# AST1060 register map
File version: 1.0
CPU: CM4 r0p1, little endian, MPU, FPU, 4 interrupt priority bits, 256 interrupts
Registers are 32-bit, read-write, reset 0x0 unless marked. A register's access mark holds for its fields unless they carry their own. Offsets are from the block's base; [hi:lo] are bit positions; {n}, {i} and the like mark numbered series; 'fields as' and 'values as' point back to an identical list.

## spi
Base 0x7E630000
Same registers: spi1 0x7E640000
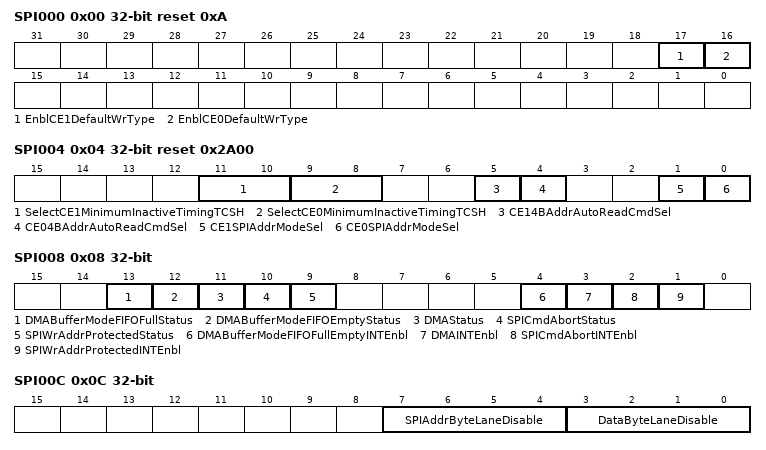
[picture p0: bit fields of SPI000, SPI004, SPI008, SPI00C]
0x00 SPI000 reset 0xA — SPI Flash Configuration Register
  [17] EnblCE1DefaultWrType — Enable CE1 default write type
  [16] EnblCE0DefaultWrType — Enable CE0 default write type
    0=CEx_Is_Default_At_Write_Disable_Mode; 1=CEx_Is_Default_At_Write_Enable_Mode
0x04 SPI004 reset 0x2A00 — CE Control Register
  [11:10] SelectCE1MinimumInactiveTimingTCSH
  [9:8] SelectCE0MinimumInactiveTimingTCSH
    0=16_X_HCLK; 1=24_X_HCLK; 2=32_X_HCLK; 3=40_X_HCLK
  [5] CE14BAddrAutoReadCmdSel — CE1 4B address Auto-Read command selection
  [4] CE04BAddrAutoReadCmdSel — CE0 4B address Auto-Read command selection
    0=Use_0x03_Command; 1=Use_0x13_Command
  [1] CE1SPIAddrModeSel — CE1 SPI address mode selection
  [0] CE0SPIAddrModeSel — CE0 SPI address mode selection
    0=3B3_Bytes_Smaller_Than_Or_Equal_To_16MB; 1=4B4_Bytes_Larger_Than_16MB
0x08 SPI008 — Interrupt Control and Status Register
  [13] DMABufferModeFIFOFullStatus ro
    0=FIFO_Is_Nonfull; 1=FIFO_Is_Full
  [12] DMABufferModeFIFOEmptyStatus ro
    0=FIFO_Is_Nonempty; 1=FIFO_Is_Empty
  [11] DMAStatus ro
    0=Busy_When_DMA_Was_Enabled_Or_Idle_When_DMA_Was_Disabled; 1=DMA_Finish
  [10] SPICmdAbortStatus — SPI Command Abort Status
  [9] SPIWrAddrProtectedStatus — SPI Write Address Protected Status
  [4] DMABufferModeFIFOFullEmptyINTEnbl — DMA Buffer Mode FIFO Full/Empty Interrupt Enable
  [3] DMAINTEnbl — DMA Interrupt Enable
  [2] SPICmdAbortINTEnbl — SPI Command Abort Interrupt Enable
  [1] SPIWrAddrProtectedINTEnbl — SPI Write Address Protected Interrupt Enable
    0=Disable; 1=Enable
0x0C SPI00C — Command Control Register
  [7:4] SPIAddrByteLaneDisable — SPI Address Byte lane disable
    0bxxx1=Disable_Address_Byte_0; 0bxx1x=Disable_Address_Byte_1; 0bx1xx=Disable_Address_Byte_2; 0b1xxx=Disable_Address_Byte_3_Only_Valid_For_4byte_Address_Mode
  [3:0] DataByteLaneDisable
    0bxxx1=Disable_Data_Byte_0; 0bxx1x=Disable_Data_Byte_1; 0bx1xx=Disable_Data_Byte_2; 0b1xxx=Disable_Data_Byte_3
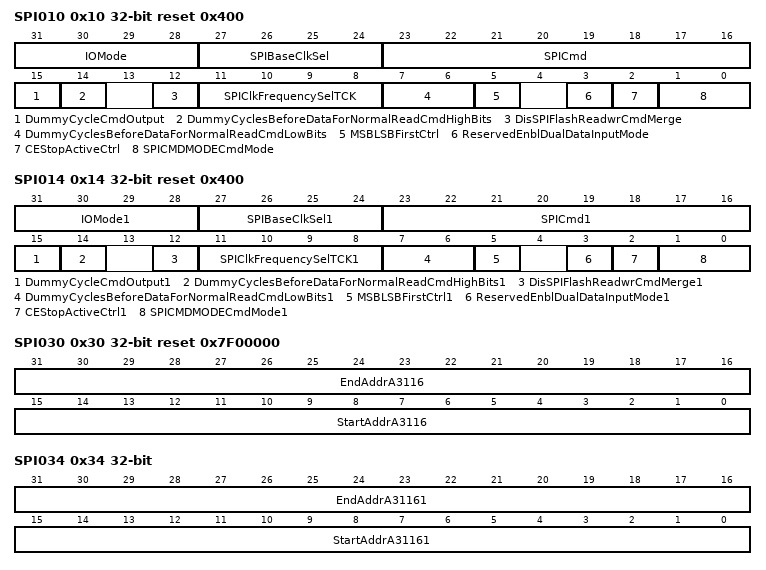
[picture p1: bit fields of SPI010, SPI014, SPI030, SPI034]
0x10 SPI010 reset 0x400 (reset mask 0xFFFFDFE7) — CE0 Control Register
  [31:28] IOMode
    0=Single_Bit; 2=Dual_Bit_Readwrite_Data_Cycle_Only; 3=Dual_Bit_Readwrite_Including_Address_And_Dummy_Byte_Cycle; 4=Quad_Bit_Readwrite_Data_Cycle_Only; 5=Quad_Bit_Readwrite_Including_Address_And_Dummy_Byte_Cycle; 0b1xxx=QPI_Mode_Quad_Bit_On_Commandaddressdata_Cycles
  [27:24] SPIBaseClkSel — SPI base clock selection
    0=Baseclk__0___THCLK; 1=Baseclk__16__THCLK; 2=Baseclk__32__THCLK; 3=Baseclk__48__THCLK; 15=Baseclk__240__THCLK
  [23:16] SPICmd — SPI Command
  [15] DummyCycleCmdOutput — Dummy cycle command output
    0=Dummy_Cycle_No_Command_Output; 1=First_Dummy_Cycle_Has_Command_Output
  [14] DummyCyclesBeforeDataForNormalReadCmdHighBits — Dummy cycles before data for Normal-Read command (high bits)
  [12] DisSPIFlashReadwrCmdMerge — Disable SPI flash read/write command merge
    0=Enable; 1=Disable_With_Performance_Penalty
  [11:8] SPIClkFrequencySelTCK — SPI clock frequency selection (t-CK)
    0=Baseclk__16__THCLK; 1=Baseclk__14__THCLK; 2=Baseclk__12__THCLK; 3=Baseclk__10__THCLK; 4=Baseclk__8__THCLKregdefmark (baseclk + (~8 * t-HCLK) egdefmark); 5=Baseclk__6__THCLK; 6=Baseclk__4__THCLK; 7=Baseclk__2__THCLK; 8=Baseclk__15__THCLK; 9=Baseclk__13__THCLK; 10=Baseclk__11__THCLK; 11=Baseclk__9__THCLK; 12=Baseclk__7__THCLK; 13=Baseclk__5__THCLK; 14=Baseclk__3__THCLK; 15=Baseclk__1__THCLK_Only_Valid_For_Baseclk_Selection_Not_Equal_To_0
  [7:6] DummyCyclesBeforeDataForNormalReadCmdLowBits — Dummy cycles before data for Normal-Read command (low bits)
  [5] MSBLSBFirstCtrl — MSB/LSB first control
    0=MSB_First_HtextAdefault_For_Boot_Code; 1=LSB_First
  [3] ReservedEnblDualDataInputMode — Reserved Enable dual data input mode
    0=28__010_Mode
  [2] CEStopActiveCtrl — CE# Stop Active Control
  [1:0] SPICMDMODECmdMode — SPICMDMODECommand Mode
    0=AutoRead_0x030x13__Address__Read_Data_1234_Bytes; 1=NormalRead_CMD__Address__Read_Data_1234_Bytes; 2=NormalWrite_CMD__Address__Write_Data_1234_Bytes; 3=UserMode_Readwrite_Data_1234_Bytes
0x14 SPI014 reset 0x400 (reset mask 0xFFFFDFE7) — CE1 Control Register
  [31:28] IOMode1 — IO Mode
    values as SPI010.IOMode
  [27:24] SPIBaseClkSel1 — SPI base clock selection
    values as SPI010.SPIBaseClkSel
  [23:16] SPICmd1 — SPI Command
  [15] DummyCycleCmdOutput1 — Dummy cycle command output
    values as SPI010.DummyCycleCmdOutput
  [14] DummyCyclesBeforeDataForNormalReadCmdHighBits1 — Dummy cycles before data for Normal-Read command (high bits)
  [12] DisSPIFlashReadwrCmdMerge1 — Disable SPI flash read/write command merge
    0=Enable; 1=Disable_With_Performance_Penalty
  [11:8] SPIClkFrequencySelTCK1 — SPI clock frequency selection (t-CK)
    values as SPI010.SPIClkFrequencySelTCK
  [7:6] DummyCyclesBeforeDataForNormalReadCmdLowBits1 — Dummy cycles before data for Normal-Read command (low bits)
  [5] MSBLSBFirstCtrl1 — MSB/LSB first control
    0=MSB_First_HtextAdefault_For_Boot_Code; 1=LSB_First
  [3] ReservedEnblDualDataInputMode1 — Reserved Enable dual data input mode
    0=28__010_Mode
  [2] CEStopActiveCtrl1 — CE# Stop Active Control
  [1:0] SPICMDMODECmdMode1 — SPICMDMODECommand Mode
    values as SPI010.SPICMDMODECmdMode
0x30 SPI030 reset 0x7F00000 — CE0 Address Decoding Range Register
  [31:16] EndAddrA3116 — End address A[31:16]
  [15:0] StartAddrA3116 — Start address A[31:16]
0x34 SPI034 — CE1 Address Decoding Range Register
  [31:16] EndAddrA31161 — End address A[31:16]
  [15:0] StartAddrA31161 — Start address A[31:16]
0x54 SPI054 — SPI Dummy Cycle Data Register
  [7:0] SPIDummyCycleOutputData
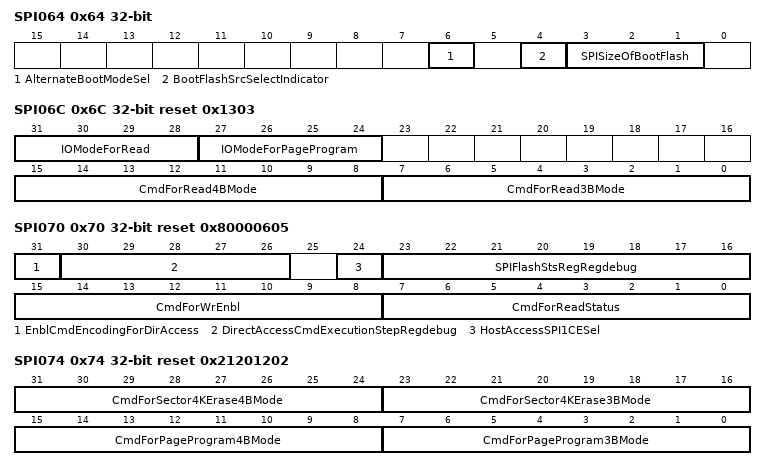
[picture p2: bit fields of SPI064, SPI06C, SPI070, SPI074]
0x64 SPI064 — Alternate Boot Control/Status
  [6] AlternateBootModeSel — Alternate Boot Mode selection
    0=2_Chips_Mode; 1=1_Chip_Mode
  [4] BootFlashSrcSelectIndicator — Boot flash source select indicator
    0=Boot_From_Primary_Source; 1=Boot_From_Alternate_Source
  [3:1] SPISizeOfBootFlash
    0=No_Define; 1=2_MB; 2=4_MB; 3=8_MB; 4=16_MB; 5=32_MB; 6=64_MB; 7=128_MB
0x6C SPI06C reset 0x1303 — Host Direct Access Commands \#4 (SPI1 only)
  [31:28] IOModeForRead
    values as SPI010.IOMode
  [27:24] IOModeForPageProgram
    values as SPI010.IOMode
  [15:8] CmdForRead4BMode — Command for Read 4B mode
  [7:0] CmdForRead3BMode — Command for Read 3B mode
0x70 SPI070 reset 0x80000605 — Host Direct Access Commands \#1 (SPI1 only)
  [31] EnblCmdEncodingForDirAccess — Enable command encoding for direct access
    0=Disable_Host_Should_Manage_The_Controller_To_Issue_The_Required_Commands; 1=Enable_Support_Encoded_Page_Program_And_Erase_Commands_Refer_Section_RefSECBSPIDMA (Enable, support encoded page program and erase commands. Refer Section ef{SECB:SPIDMA.)
  [30:26] DirectAccessCmdExecutionStepRegdebug ro — Direct access command execution step regdebug
    0=Idle
  [24] HostAccessSPI1CESel — Host access SPI1 CE selection
    0=CE0; 1=CE1
  [23:16] SPIFlashStsRegRegdebug ro — SPI flash status register regdebug
  [15:8] CmdForWrEnbl — Command for Write Enable
  [7:0] CmdForReadStatus — Command for Read Status
0x74 SPI074 reset 0x21201202 — Host Direct Access Commands \#2 (SPI1 only)
  [31:24] CmdForSector4KErase4BMode — Command for Sector (4K) Erase 4B mode
  [23:16] CmdForSector4KErase3BMode — Command for Sector (4K) Erase 3B mode
  [15:8] CmdForPageProgram4BMode — Command for Page Program 4B mode
  [7:0] CmdForPageProgram3BMode — Command for Page Program 3B mode
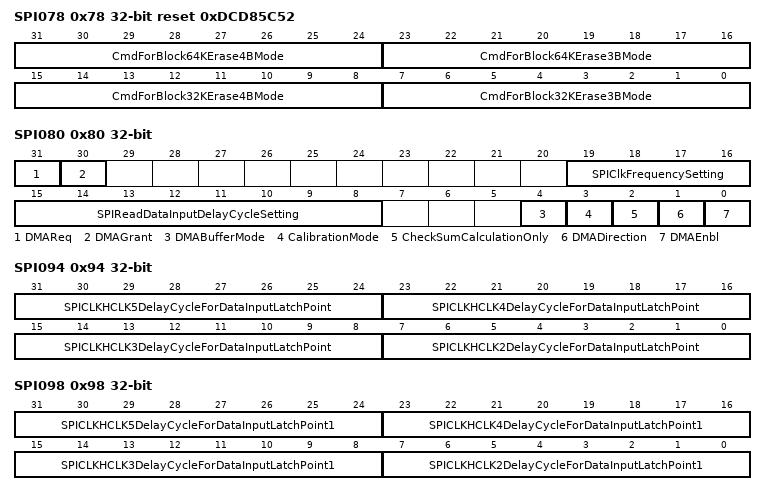
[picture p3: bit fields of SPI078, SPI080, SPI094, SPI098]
0x78 SPI078 reset 0xDCD85C52 — Host Direct Access Commands \#3 (SPI1 only)
  [31:24] CmdForBlock64KErase4BMode — Command for Block (64K) Erase 4B mode
  [23:16] CmdForBlock64KErase3BMode — Command for Block (64K) Erase 3B mode
  [15:8] CmdForBlock32KErase4BMode — Command for Block (32K) Erase 4B mode
  [7:0] CmdForBlock32KErase3BMode — Command for Block (32K) Erase 3B mode
0x7C SPI07C — DMA Buffer Mode Length Register
  [6:0] FIFOLengthStatus
0x80 SPI080 — DMA Control/Status Register
  [31] DMAReq — DMA Request
  [30] DMAGrant ro
    0=DMA_Is_Not_Allowed_To_Be_Used_All_DMA_Related_Control_Registers_Are_Not_Allowed_To_Be_Written; 1=DMA_Is_Granted_To_Be_Used
  [19:16] SPIClkFrequencySetting — SPI clock frequency setting
  [15:8] SPIReadDataInputDelayCycleSetting
  [4] DMABufferMode
    0=Memory_Mode_Transfer_Tofrom_DRAMSRAM; 1=Buffer_Mode_Transfer_Tofrom_DMA_Buffer_The_DMA_Buffer_Works_As_FIFO_Mode_For_Data_Transfer_And_DMA_Will_Stop_Temporarily_When_FIFO_Is_Empty_Or_Full
  [3] CalibrationMode
    0=Normal_Mode; 1=Calibration_Mode_At_This_Mode_SPI_Clock_Rate_And_Read_Delay_Cycle_Parameters
  [2] CheckSumCalculationOnly
    0=Normal_DMA_Operation; 1=Checksum_Accumulation_Only
  [1] DMADirection
    0=Read_Flash_Move_From_Flash_To_External_Memory; 1=Write_Flash_Move_From_External_Memory_To_Flash
  [0] DMAEnbl — DMA Enable
    0=Disable; 1=Enable_DMA_Operation
0x84 SPI084 — DMA Flash Side Address
  [27:2] FlashSideStartAddr — Flash side start address
0x88 SPI088 — DMA DRAM/SRAM Side Address
  [31:2] DRAMSideStartAddrMemoryModeOnly — DRAM side start address (Memory mode only)
0x8C SPI08C — DMA Length Register
  [24:0] DMALength
0x90 SPI090 — CheckSum Calculation Result
  [31:0] CheckSumCalculationResult ro
0x94 SPI094 — CE0 SPI Flash Read Timing Compensation
  [8n-9:8n-16] SPICLKHCLK{n}DelayCycleForDataInputLatchPoint (n=2..5)
0x98 SPI098 — CE1 SPI Flash Read Timing Compensation
  [8n-9:8n-16] SPICLKHCLK{n}DelayCycleForDataInputLatchPoint1 (n=2..5) — SPICLK = HCLK/{n}, delay cycle for data input latch point
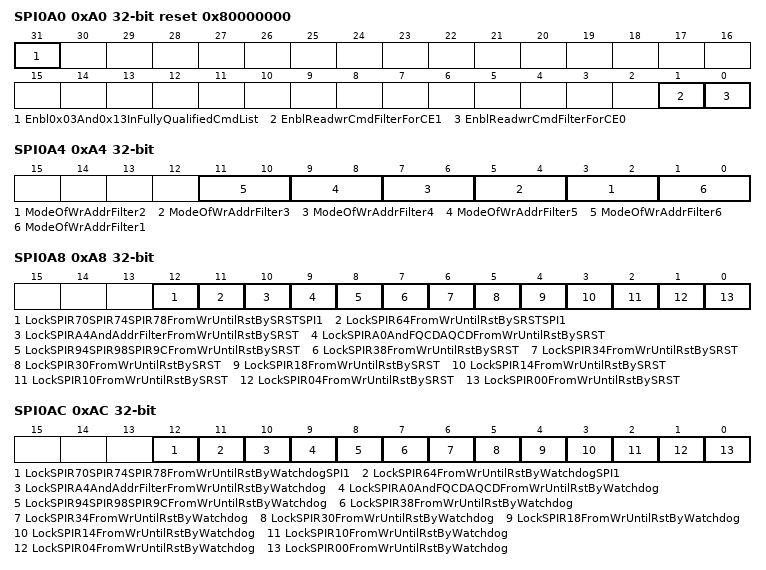
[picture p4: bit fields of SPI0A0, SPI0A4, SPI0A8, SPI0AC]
0xA0 SPI0A0 reset 0x80000000 — Command Filter Control Register
  [31] Enbl0x03And0x13InFullyQualifiedCmdList — Enable 0x03 and 0x13 in Fully Qualified Command list
  [1] EnblReadwrCmdFilterForCE1 — Enable read/write command filter for CE1
  [0] EnblReadwrCmdFilterForCE0 — Enable read/write command filter for CE0
    0=Disable_Filter_All_Commands_Are_Allowed; 1=Enable_Filter_Only_Commands_Defined_In_HlinkSPIR100_Sim_HlinkSPIR17C_Are_Allowed
0xA4 SPI0A4 — Write Address Filter Control Register
  [2n-1:2n-2] ModeOfWrAddrFilter{n} (n=2..6) — Mode of write address filter #{n}
  [1:0] ModeOfWrAddrFilter1 — Mode of write address filter #1
    0=NOP; 1=Read_Only; 2=Write_Only; 3=Access_Disabled
0xA8 SPI0A8 — Register Lock Control Register (SRST\#)
  [12] LockSPIR70SPIR74SPIR78FromWrUntilRstBySRSTSPI1 — Lock SPIR70/SPIR74/SPIR78 from write until reset by SRST# (SPI1)
  [11] LockSPIR64FromWrUntilRstBySRSTSPI1 — Lock SPIR64 from write until reset by SRST# (SPI1)
  [10] LockSPIRA4AndAddrFilterFromWrUntilRstBySRST — Lock SPIRA4 and Address Filter from write until reset by SRST#
  [9] LockSPIRA0AndFQCDAQCDFromWrUntilRstBySRST — Lock SPIRA0 and FQCD/AQCD from write until reset by SRST#
  [8] LockSPIR94SPIR98SPIR9CFromWrUntilRstBySRST — Lock SPIR94/SPIR98/SPIR9C from write until reset by SRST#
  [7] LockSPIR38FromWrUntilRstBySRST — Lock SPIR38 from write until reset by SRST#
  [6] LockSPIR34FromWrUntilRstBySRST — Lock SPIR34 from write until reset by SRST#
  [5] LockSPIR30FromWrUntilRstBySRST — Lock SPIR30 from write until reset by SRST#
  [4] LockSPIR18FromWrUntilRstBySRST — Lock SPIR18 from write until reset by SRST#
  [3] LockSPIR14FromWrUntilRstBySRST — Lock SPIR14 from write until reset by SRST#
  [2] LockSPIR10FromWrUntilRstBySRST — Lock SPIR10 from write until reset by SRST#
  [1] LockSPIR04FromWrUntilRstBySRST — Lock SPIR04 from write until reset by SRST#
  [0] LockSPIR00FromWrUntilRstBySRST — Lock SPIR00 from write until reset by SRST#
0xAC SPI0AC — Register Lock Control Register (Watchdog)
  [12] LockSPIR70SPIR74SPIR78FromWrUntilRstByWatchdogSPI1 — Lock SPIR70/SPIR74/SPIR78 from write until reset by watchdog (SPI1)
  [11] LockSPIR64FromWrUntilRstByWatchdogSPI1 — Lock SPIR64 from write until reset by watchdog (SPI1)
  [10] LockSPIRA4AndAddrFilterFromWrUntilRstByWatchdog — Lock SPIRA4 and Address Filter from write until reset by watchdog
  [9] LockSPIRA0AndFQCDAQCDFromWrUntilRstByWatchdog — Lock SPIRA0 and FQCD/AQCD from write until reset by watchdog
  [8] LockSPIR94SPIR98SPIR9CFromWrUntilRstByWatchdog — Lock SPIR94/SPIR98/SPIR9C from write until reset by watchdog
  [7] LockSPIR38FromWrUntilRstByWatchdog — Lock SPIR38 from write until reset by watchdog
  [6] LockSPIR34FromWrUntilRstByWatchdog — Lock SPIR34 from write until reset by watchdog
  [5] LockSPIR30FromWrUntilRstByWatchdog — Lock SPIR30 from write until reset by watchdog
  [4] LockSPIR18FromWrUntilRstByWatchdog — Lock SPIR18 from write until reset by watchdog
  [3] LockSPIR14FromWrUntilRstByWatchdog — Lock SPIR14 from write until reset by watchdog
  [2] LockSPIR10FromWrUntilRstByWatchdog — Lock SPIR10 from write until reset by watchdog
  [1] LockSPIR04FromWrUntilRstByWatchdog — Lock SPIR04 from write until reset by watchdog
  [0] LockSPIR00FromWrUntilRstByWatchdog — Lock SPIR00 from write until reset by watchdog
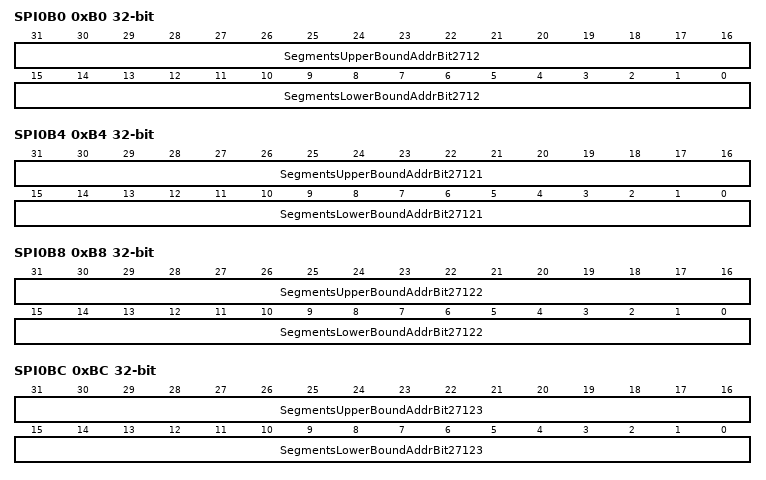
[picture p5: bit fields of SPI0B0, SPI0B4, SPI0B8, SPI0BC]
0xB0 SPI0B0 — Write Address Filter Register \#1
  [31:16] SegmentsUpperBoundAddrBit2712 — Segments Upper bound address bit[27:12]
  [15:0] SegmentsLowerBoundAddrBit2712 — Segments Lower bound address bit[27:12]
0xB4 SPI0B4 — Write Address Filter Register \#2
  [31:16] SegmentsUpperBoundAddrBit27121 — Segments Upper bound address bit[27:12]
  [15:0] SegmentsLowerBoundAddrBit27121 — Segments Lower bound address bit[27:12]
0xB8 SPI0B8 — Write Address Filter Register \#3
  [31:16] SegmentsUpperBoundAddrBit27122 — Segments Upper bound address bit[27:12]
  [15:0] SegmentsLowerBoundAddrBit27122 — Segments Lower bound address bit[27:12]
0xBC SPI0BC — Write Address Filter Register \#4
  [31:16] SegmentsUpperBoundAddrBit27123 — Segments Upper bound address bit[27:12]
  [15:0] SegmentsLowerBoundAddrBit27123 — Segments Lower bound address bit[27:12]
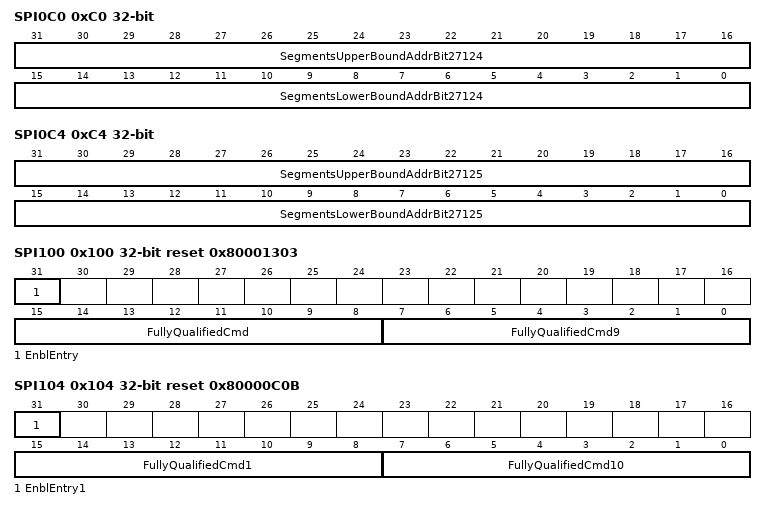
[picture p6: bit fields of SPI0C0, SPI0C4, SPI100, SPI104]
0xC0 SPI0C0 — Write Address Filter Register \#5
  [31:16] SegmentsUpperBoundAddrBit27124 — Segments Upper bound address bit[27:12]
  [15:0] SegmentsLowerBoundAddrBit27124 — Segments Lower bound address bit[27:12]
0xC4 SPI0C4 — Write Address Filter Register \#6
  [31:16] SegmentsUpperBoundAddrBit27125 — Segments Upper bound address bit[27:12]
  [15:0] SegmentsLowerBoundAddrBit27125 — Segments Lower bound address bit[27:12]
0x100 SPI100 reset 0x80001303 — Fully Qualified Command
  [31] EnblEntry — Enable Entry
  [15:8] FullyQualifiedCmd — Fully qualified Command
  [7:0] FullyQualifiedCmd9 — Fully qualified Command
0x104 SPI104 reset 0x80000C0B — Fully Qualified Command
  [31] EnblEntry1 — Enable Entry
  [15:8] FullyQualifiedCmd1 — Fully qualified Command
  [7:0] FullyQualifiedCmd10 — Fully qualified Command
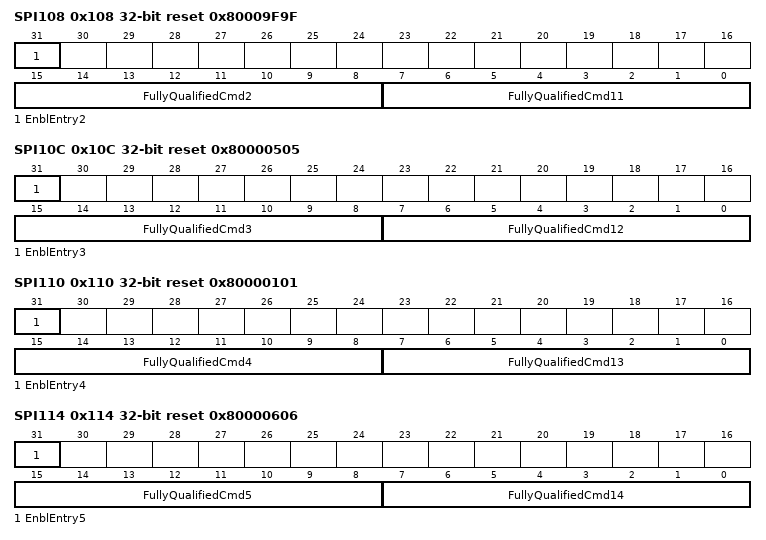
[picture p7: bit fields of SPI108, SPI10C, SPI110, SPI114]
0x108 SPI108 reset 0x80009F9F — Fully Qualified Command
  [31] EnblEntry2 — Enable Entry
  [15:8] FullyQualifiedCmd2 — Fully qualified Command
  [7:0] FullyQualifiedCmd11 — Fully qualified Command
0x10C SPI10C reset 0x80000505 — Fully Qualified Command
  [31] EnblEntry3 — Enable Entry
  [15:8] FullyQualifiedCmd3 — Fully qualified Command
  [7:0] FullyQualifiedCmd12 — Fully qualified Command
0x110 SPI110 reset 0x80000101 — Fully Qualified Command
  [31] EnblEntry4 — Enable Entry
  [15:8] FullyQualifiedCmd4 — Fully qualified Command
  [7:0] FullyQualifiedCmd13 — Fully qualified Command
0x114 SPI114 reset 0x80000606 — Fully Qualified Command
  [31] EnblEntry5 — Enable Entry
  [15:8] FullyQualifiedCmd5 — Fully qualified Command
  [7:0] FullyQualifiedCmd14 — Fully qualified Command
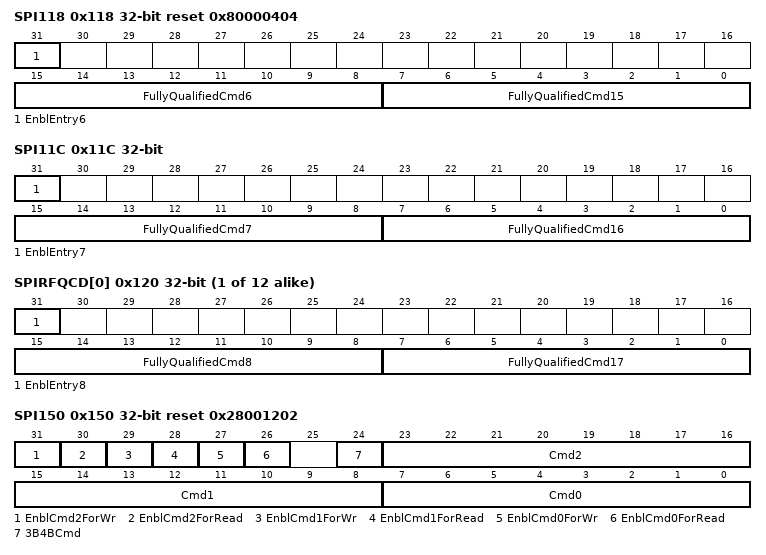
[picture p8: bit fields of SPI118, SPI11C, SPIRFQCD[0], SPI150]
0x118 SPI118 reset 0x80000404 — Fully Qualified Command
  [31] EnblEntry6 — Enable Entry
  [15:8] FullyQualifiedCmd6 — Fully qualified Command
  [7:0] FullyQualifiedCmd15 — Fully qualified Command
0x11C SPI11C — Fully Qualified Command
  [31] EnblEntry7 — Enable Entry
  [15:8] FullyQualifiedCmd7 — Fully qualified Command
  [7:0] FullyQualifiedCmd16 — Fully qualified Command
{0x120+4i} SPIRFQCD[{i}] (i=0..11) — Fully Qualified Command
  [31] EnblEntry8 — Enable Entry
  [15:8] FullyQualifiedCmd8 — Fully qualified Command
  [7:0] FullyQualifiedCmd17 — Fully qualified Command
0x150 SPI150 reset 0x28001202 — Address Qualified Command
  [31] EnblCmd2ForWr — Enable Command 2 for write
  [30] EnblCmd2ForRead — Enable Command 2 for read
  [29] EnblCmd1ForWr — Enable Command 1 for write
  [28] EnblCmd1ForRead — Enable Command 1 for read
  [27] EnblCmd0ForWr — Enable Command 0 for write
  [26] EnblCmd0ForRead — Enable Command 0 for read
  [24] 3B4BCmd — 3B/4B Command
    0=Command_210_Are_For_3B_Mode; 1=Command_210_Are_For_4B_Mode
  [23:16] Cmd2 — Command 2
  [15:8] Cmd1 — Command 1
  [7:0] Cmd0 — Command 0
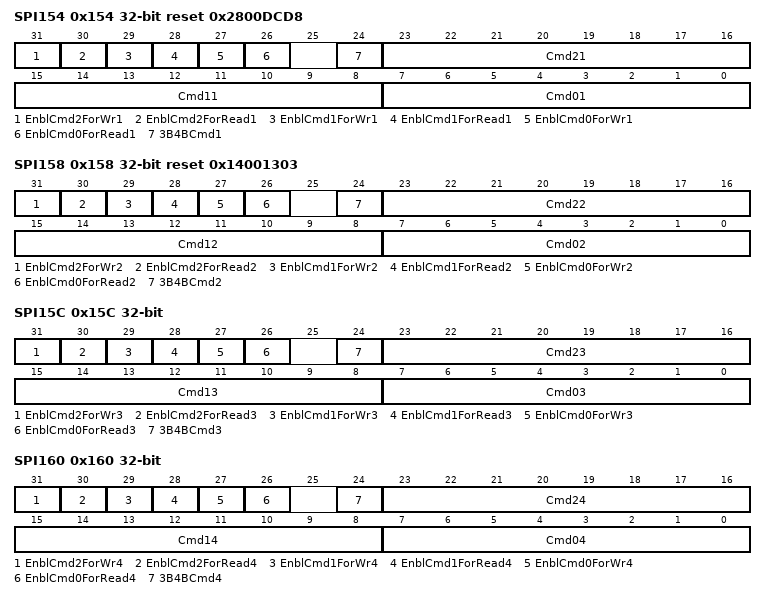
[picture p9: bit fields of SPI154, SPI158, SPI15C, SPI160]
0x154 SPI154 reset 0x2800DCD8 — Address Qualified Command
  [31] EnblCmd2ForWr1 — Enable Command 2 for write
  [30] EnblCmd2ForRead1 — Enable Command 2 for read
  [29] EnblCmd1ForWr1 — Enable Command 1 for write
  [28] EnblCmd1ForRead1 — Enable Command 1 for read
  [27] EnblCmd0ForWr1 — Enable Command 0 for write
  [26] EnblCmd0ForRead1 — Enable Command 0 for read
  [24] 3B4BCmd1 — 3B/4B Command
    0=Command_210_Are_For_3B_Mode; 1=Command_210_Are_For_4B_Mode
  [23:16] Cmd21 — Command 2
  [15:8] Cmd11 — Command 1
  [7:0] Cmd01 — Command 0
0x158 SPI158 reset 0x14001303 — Address Qualified Command
  [31] EnblCmd2ForWr2 — Enable Command 2 for write
  [30] EnblCmd2ForRead2 — Enable Command 2 for read
  [29] EnblCmd1ForWr2 — Enable Command 1 for write
  [28] EnblCmd1ForRead2 — Enable Command 1 for read
  [27] EnblCmd0ForWr2 — Enable Command 0 for write
  [26] EnblCmd0ForRead2 — Enable Command 0 for read
  [24] 3B4BCmd2 — 3B/4B Command
    0=Command_210_Are_For_3B_Mode; 1=Command_210_Are_For_4B_Mode
  [23:16] Cmd22 — Command 2
  [15:8] Cmd12 — Command 1
  [7:0] Cmd02 — Command 0
0x15C SPI15C — Address Qualified Command
  [31] EnblCmd2ForWr3 — Enable Command 2 for write
  [30] EnblCmd2ForRead3 — Enable Command 2 for read
  [29] EnblCmd1ForWr3 — Enable Command 1 for write
  [28] EnblCmd1ForRead3 — Enable Command 1 for read
  [27] EnblCmd0ForWr3 — Enable Command 0 for write
  [26] EnblCmd0ForRead3 — Enable Command 0 for read
  [24] 3B4BCmd3 — 3B/4B Command
    0=Command_210_Are_For_3B_Mode; 1=Command_210_Are_For_4B_Mode
  [23:16] Cmd23 — Command 2
  [15:8] Cmd13 — Command 1
  [7:0] Cmd03 — Command 0
0x160 SPI160 — Address Qualified Command
  [31] EnblCmd2ForWr4 — Enable Command 2 for write
  [30] EnblCmd2ForRead4 — Enable Command 2 for read
  [29] EnblCmd1ForWr4 — Enable Command 1 for write
  [28] EnblCmd1ForRead4 — Enable Command 1 for read
  [27] EnblCmd0ForWr4 — Enable Command 0 for write
  [26] EnblCmd0ForRead4 — Enable Command 0 for read
  [24] 3B4BCmd4 — 3B/4B Command
    0=Command_210_Are_For_3B_Mode; 1=Command_210_Are_For_4B_Mode
  [23:16] Cmd24 — Command 2
  [15:8] Cmd14 — Command 1
  [7:0] Cmd04 — Command 0
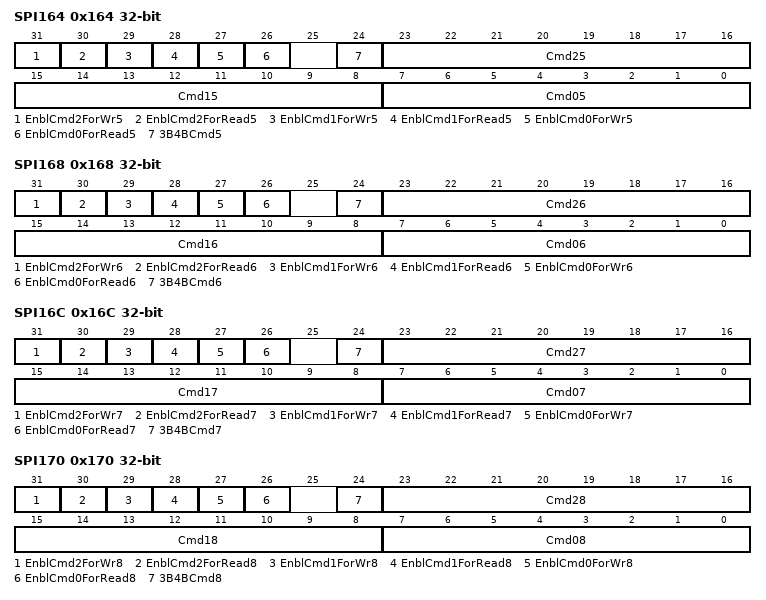
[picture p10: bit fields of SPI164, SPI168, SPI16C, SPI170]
0x164 SPI164 — Address Qualified Command
  [31] EnblCmd2ForWr5 — Enable Command 2 for write
  [30] EnblCmd2ForRead5 — Enable Command 2 for read
  [29] EnblCmd1ForWr5 — Enable Command 1 for write
  [28] EnblCmd1ForRead5 — Enable Command 1 for read
  [27] EnblCmd0ForWr5 — Enable Command 0 for write
  [26] EnblCmd0ForRead5 — Enable Command 0 for read
  [24] 3B4BCmd5 — 3B/4B Command
    0=Command_210_Are_For_3B_Mode; 1=Command_210_Are_For_4B_Mode
  [23:16] Cmd25 — Command 2
  [15:8] Cmd15 — Command 1
  [7:0] Cmd05 — Command 0
0x168 SPI168 — Address Qualified Command
  [31] EnblCmd2ForWr6 — Enable Command 2 for write
  [30] EnblCmd2ForRead6 — Enable Command 2 for read
  [29] EnblCmd1ForWr6 — Enable Command 1 for write
  [28] EnblCmd1ForRead6 — Enable Command 1 for read
  [27] EnblCmd0ForWr6 — Enable Command 0 for write
  [26] EnblCmd0ForRead6 — Enable Command 0 for read
  [24] 3B4BCmd6 — 3B/4B Command
    0=Command_210_Are_For_3B_Mode; 1=Command_210_Are_For_4B_Mode
  [23:16] Cmd26 — Command 2
  [15:8] Cmd16 — Command 1
  [7:0] Cmd06 — Command 0
0x16C SPI16C — Address Qualified Command
  [31] EnblCmd2ForWr7 — Enable Command 2 for write
  [30] EnblCmd2ForRead7 — Enable Command 2 for read
  [29] EnblCmd1ForWr7 — Enable Command 1 for write
  [28] EnblCmd1ForRead7 — Enable Command 1 for read
  [27] EnblCmd0ForWr7 — Enable Command 0 for write
  [26] EnblCmd0ForRead7 — Enable Command 0 for read
  [24] 3B4BCmd7 — 3B/4B Command
    0=Command_210_Are_For_3B_Mode; 1=Command_210_Are_For_4B_Mode
  [23:16] Cmd27 — Command 2
  [15:8] Cmd17 — Command 1
  [7:0] Cmd07 — Command 0
0x170 SPI170 — Address Qualified Command
  [31] EnblCmd2ForWr8 — Enable Command 2 for write
  [30] EnblCmd2ForRead8 — Enable Command 2 for read
  [29] EnblCmd1ForWr8 — Enable Command 1 for write
  [28] EnblCmd1ForRead8 — Enable Command 1 for read
  [27] EnblCmd0ForWr8 — Enable Command 0 for write
  [26] EnblCmd0ForRead8 — Enable Command 0 for read
  [24] 3B4BCmd8 — 3B/4B Command
    0=Command_210_Are_For_3B_Mode; 1=Command_210_Are_For_4B_Mode
  [23:16] Cmd28 — Command 2
  [15:8] Cmd18 — Command 1
  [7:0] Cmd08 — Command 0
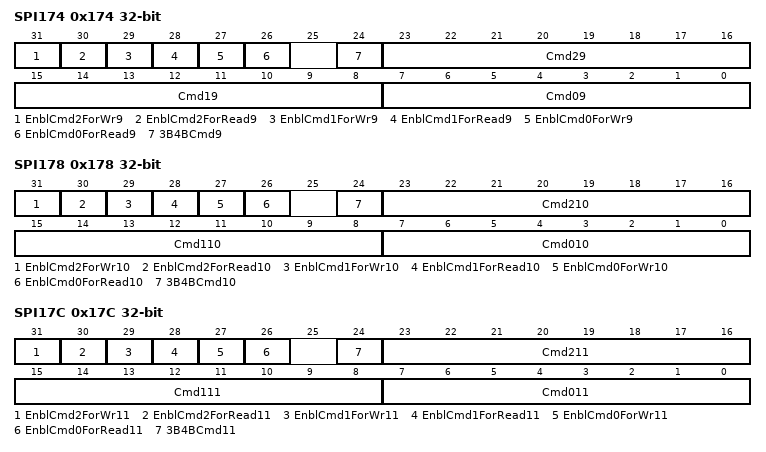
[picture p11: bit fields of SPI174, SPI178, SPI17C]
0x174 SPI174 — Address Qualified Command
  [31] EnblCmd2ForWr9 — Enable Command 2 for write
  [30] EnblCmd2ForRead9 — Enable Command 2 for read
  [29] EnblCmd1ForWr9 — Enable Command 1 for write
  [28] EnblCmd1ForRead9 — Enable Command 1 for read
  [27] EnblCmd0ForWr9 — Enable Command 0 for write
  [26] EnblCmd0ForRead9 — Enable Command 0 for read
  [24] 3B4BCmd9 — 3B/4B Command
    0=Command_210_Are_For_3B_Mode; 1=Command_210_Are_For_4B_Mode
  [23:16] Cmd29 — Command 2
  [15:8] Cmd19 — Command 1
  [7:0] Cmd09 — Command 0
0x178 SPI178 — Address Qualified Command
  [31] EnblCmd2ForWr10 — Enable Command 2 for write
  [30] EnblCmd2ForRead10 — Enable Command 2 for read
  [29] EnblCmd1ForWr10 — Enable Command 1 for write
  [28] EnblCmd1ForRead10 — Enable Command 1 for read
  [27] EnblCmd0ForWr10 — Enable Command 0 for write
  [26] EnblCmd0ForRead10 — Enable Command 0 for read
  [24] 3B4BCmd10 — 3B/4B Command
    0=Command_210_Are_For_3B_Mode; 1=Command_210_Are_For_4B_Mode
  [23:16] Cmd210 — Command 2
  [15:8] Cmd110 — Command 1
  [7:0] Cmd010 — Command 0
0x17C SPI17C — Address Qualified Command
  [31] EnblCmd2ForWr11 — Enable Command 2 for write
  [30] EnblCmd2ForRead11 — Enable Command 2 for read
  [29] EnblCmd1ForWr11 — Enable Command 1 for write
  [28] EnblCmd1ForRead11 — Enable Command 1 for read
  [27] EnblCmd0ForWr11 — Enable Command 0 for write
  [26] EnblCmd0ForRead11 — Enable Command 0 for read
  [24] 3B4BCmd11 — 3B/4B Command
    0=Command_210_Are_For_3B_Mode; 1=Command_210_Are_For_4B_Mode
  [23:16] Cmd211 — Command 2
  [15:8] Cmd111 — Command 1
  [7:0] Cmd011 — Command 0
{0x200+4i} SPIRBUF[{i}] (i=0..63) — DMA Buffer R/W Port
  [31:0] DMABufferReadwrPort — DMA Buffer read/write port
